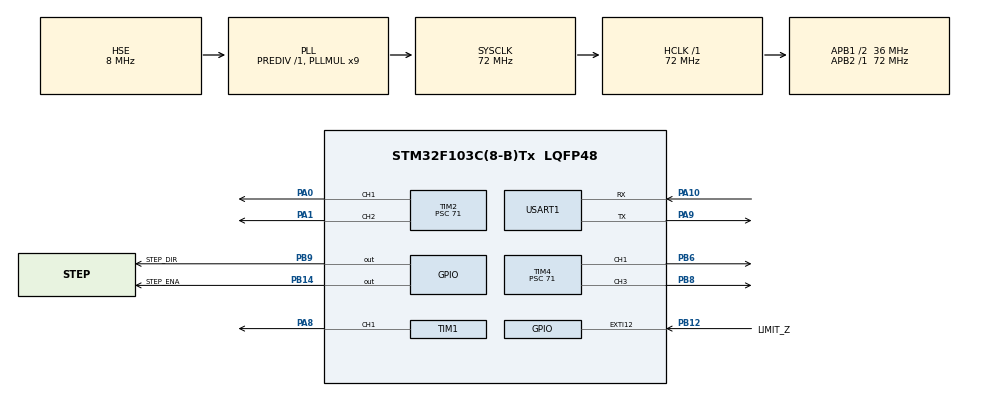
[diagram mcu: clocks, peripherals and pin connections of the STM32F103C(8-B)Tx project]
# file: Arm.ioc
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Mcu.Family=STM32F1
Mcu.Name=STM32F103C(8-B)Tx
Mcu.Package=LQFP48
NVIC.EXTI15_10_IRQn=true\:1\:0\:true\:false\:true\:true\:true
NVIC.PriorityGroup=NVIC_PRIORITYGROUP_4
NVIC.TIM1_UP_IRQn=true\:1\:0\:true\:false\:true\:true\:true
PA0-WKUP.Signal=S_TIM2_CH1_ETR
PA1.Signal=S_TIM2_CH2
PA10.Mode=Asynchronous
PA10.Signal=USART1_RX
PA13.Mode=Serial_Wire
PA13.Signal=SYS_JTMS-SWDIO
PA14.Mode=Serial_Wire
PA14.Signal=SYS_JTCK-SWCLK
PA8.Signal=S_TIM1_CH1
PA9.Mode=Asynchronous
PA9.Signal=USART1_TX
PB12.GPIO_Label=LIMIT_Z
PB12.GPIO_ModeDefaultEXTI=GPIO_MODE_IT_FALLING
PB12.GPIO_PuPd=GPIO_PULLUP
PB12.Signal=GPXTI12
PB14.GPIO_Label=STEP_ENA
PB14.PinState=GPIO_PIN_SET
PB14.Signal=GPIO_Output
PB6.Signal=S_TIM4_CH1
PB8.Signal=S_TIM4_CH3
PB9.GPIO_Label=STEP_DIR
PB9.Signal=GPIO_Output
PD0-OSC_IN.Mode=HSE-External-Oscillator
PD0-OSC_IN.Signal=RCC_OSC_IN
PD1-OSC_OUT.Mode=HSE-External-Oscillator
PD1-OSC_OUT.Signal=RCC_OSC_OUT
ProjectManager.HeapSize=0x200
ProjectManager.StackSize=0x1000
ProjectManager.TargetToolchain=MDK-ARM V5
RCC.AHBFreq_Value=72000000
RCC.APB1CLKDivider=RCC_HCLK_DIV2
RCC.APB1Freq_Value=36000000
RCC.APB1TimFreq_Value=72000000
RCC.APB2Freq_Value=72000000
RCC.APB2TimFreq_Value=72000000
RCC.HCLKFreq_Value=72000000
RCC.PLLMUL=RCC_PLL_MUL9
RCC.PLLSourceVirtual=RCC_PLLSOURCE_HSE
RCC.SYSCLKFreq_VALUE=72000000
RCC.SYSCLKSource=RCC_SYSCLKSOURCE_PLLCLK
RCC.USBFreq_Value=72000000
SH.S_TIM1_CH1.0=TIM1_CH1,PWM Generation1 CH1
SH.S_TIM2_CH1_ETR.0=TIM2_CH1,PWM Generation1 CH1
SH.S_TIM2_CH2.0=TIM2_CH2,PWM Generation2 CH2
SH.S_TIM4_CH1.0=TIM4_CH1,PWM Generation1 CH1
SH.S_TIM4_CH3.0=TIM4_CH3,PWM Generation3 CH3
TIM1.AutoReloadPreload=TIM_AUTORELOAD_PRELOAD_ENABLE
TIM1.Channel-PWM\ Generation1\ CH1=TIM_CHANNEL_1
TIM1.Period=499
TIM1.Prescaler=71
TIM1.Pulse-PWM\ Generation1\ CH1=250
TIM2.AutoReloadPreload=TIM_AUTORELOAD_PRELOAD_ENABLE
TIM2.Channel-PWM\ Generation1\ CH1=TIM_CHANNEL_1
TIM2.Channel-PWM\ Generation2\ CH2=TIM_CHANNEL_2
TIM2.Period=19999
TIM2.Prescaler=71
TIM2.Pulse-PWM\ Generation1\ CH1=1500
TIM2.Pulse-PWM\ Generation2\ CH2=1500
TIM4.AutoReloadPreload=TIM_AUTORELOAD_PRELOAD_ENABLE
TIM4.Channel-PWM\ Generation1\ CH1=TIM_CHANNEL_1
TIM4.Channel-PWM\ Generation3\ CH3=TIM_CHANNEL_3
TIM4.Period=19999
TIM4.Prescaler=71
TIM4.Pulse-PWM\ Generation1\ CH1=1500
TIM4.Pulse-PWM\ Generation3\ CH3=1500
USART1.VirtualMode=VM_ASYNC
VP_TIM1_VS_ClockSourceINT.Mode=Internal
VP_TIM2_VS_ClockSourceINT.Mode=Internal
VP_TIM4_VS_ClockSourceINT.Mode=Internal
board=custom

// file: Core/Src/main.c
/* USER CODE BEGIN Header */
/**
  ******************************************************************************
  * @file           : main.c
  * @brief          : Main program body
  ******************************************************************************
  * @attention
  *
  * <h2><center>&copy; Copyright (c) 2026 STMicroelectronics.
  * All rights reserved.</center></h2>
  *
  * This software component is licensed by ST under BSD 3-Clause license,
  * the "License"; You may not use this file except in compliance with the
  * License. You may obtain a copy of the License at:
  *                        opensource.org/licenses/BSD-3-Clause
  *
  ******************************************************************************
  */
/* USER CODE END Header */
#include "main.h"
#include "tim.h"
#include "usart.h"
#include "gpio.h"

/* USER CODE BEGIN Includes */
#include "app_main.h"
/* USER CODE END Includes */

void SystemClock_Config(void);

int main(void)
{

  /* MCU Configuration--------------------------------------------------------*/

  /* Reset of all peripherals, Initializes the Flash interface and the Systick. */
  HAL_Init();

  /* Configure the system clock */
  SystemClock_Config();

  /* Initialize all configured peripherals */
  MX_GPIO_Init();
  MX_TIM1_Init();
  MX_TIM2_Init();
  MX_TIM4_Init();
  MX_USART1_UART_Init();
  /* USER CODE BEGIN 2 */
  app_init();                       // 舵机回中位、步进初始化、打印版本
  /* USER CODE END 2 */

  /* Infinite loop */
  while (1)
  {

    /* USER CODE BEGIN 3 */
    app_loop();                     // 收串口、跑 20ms 节拍、查故障
  }
  /* USER CODE END 3 */
}

void SystemClock_Config(void)
{
  RCC_OscInitTypeDef RCC_OscInitStruct = {0};
  RCC_ClkInitTypeDef RCC_ClkInitStruct = {0};

  /** Initializes the RCC Oscillators according to the specified parameters
  * in the RCC_OscInitTypeDef structure.
  */
  RCC_OscInitStruct.OscillatorType = RCC_OSCILLATORTYPE_HSE;
  RCC_OscInitStruct.HSEState = RCC_HSE_ON;
  RCC_OscInitStruct.HSEPredivValue = RCC_HSE_PREDIV_DIV1;
  RCC_OscInitStruct.HSIState = RCC_HSI_ON;
  RCC_OscInitStruct.PLL.PLLState = RCC_PLL_ON;
  RCC_OscInitStruct.PLL.PLLSource = RCC_PLLSOURCE_HSE;
  RCC_OscInitStruct.PLL.PLLMUL = RCC_PLL_MUL9;
  if (HAL_RCC_OscConfig(&RCC_OscInitStruct) != HAL_OK)
  {
    Error_Handler();
  }
  /** Initializes the CPU, AHB and APB buses clocks
  */
  RCC_ClkInitStruct.ClockType = RCC_CLOCKTYPE_HCLK|RCC_CLOCKTYPE_SYSCLK
                              |RCC_CLOCKTYPE_PCLK1|RCC_CLOCKTYPE_PCLK2;
  RCC_ClkInitStruct.SYSCLKSource = RCC_SYSCLKSOURCE_PLLCLK;
  RCC_ClkInitStruct.AHBCLKDivider = RCC_SYSCLK_DIV1;
  RCC_ClkInitStruct.APB1CLKDivider = RCC_HCLK_DIV2;
  RCC_ClkInitStruct.APB2CLKDivider = RCC_HCLK_DIV1;

  if (HAL_RCC_ClockConfig(&RCC_ClkInitStruct, FLASH_LATENCY_2) != HAL_OK)
  {
    Error_Handler();
  }
}

void Error_Handler(void)
{
  __disable_irq();
  while (1)
  {
  }
}

/************************ (C) COPYRIGHT STMicroelectronics *****END OF FILE****/
